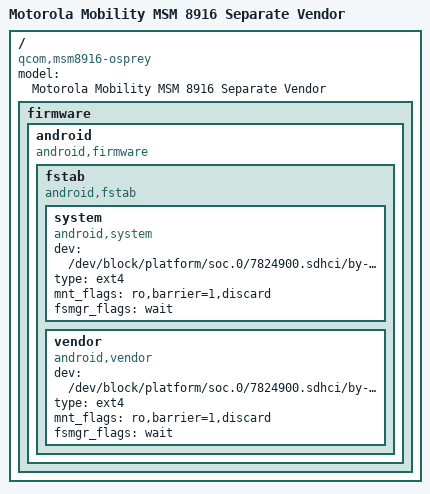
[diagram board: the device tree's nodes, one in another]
/* Copyright (c) 2013-2016, The Linux Foundation. All rights reserved.
 *
 * This program is free software; you can redistribute it and/or modify
 * it under the terms of the GNU General Public License version 2 and
 * only version 2 as published by the Free Software Foundation.
 *
 * This program is distributed in the hope that it will be useful,
 * but WITHOUT ANY WARRANTY; without even the implied warranty of
 * MERCHANTABILITY or FITNESS FOR A PARTICULAR PURPOSE.  See the
 * GNU General Public License for more details.
 */

#include "msm8916.dtsi"
/ {
	model = "Motorola Mobility MSM 8916 Separate Vendor";
	compatible = "qcom,msm8916-osprey", "qcom,msm8916-moto", "qcom,msm8916";

        firmware: firmware {
                 android {
                         compatible = "android,firmware";
                         fstab {
                                 compatible = "android,fstab";
                                 system {
                                         compatible = "android,system";
                                         dev = "/dev/block/platform/soc.0/7824900.sdhci/by-name/system";
                                         type = "ext4";
                                         mnt_flags = "ro,barrier=1,discard";
                                         fsmgr_flags = "wait";
                                         status = "ok";
                                        };
				 vendor {
					 compatible = "android,vendor";
					 dev = "/dev/block/platform/soc.0/7824900.sdhci/by-name/cache";
					 type = "ext4";
					 mnt_flags = "ro,barrier=1,discard";
					 fsmgr_flags = "wait";
					 status = "ok";	 
                                 };
                         };
                 };
        };

};
